AUTOSAR XML (schema 4-2-2)
package /ComponentTypes
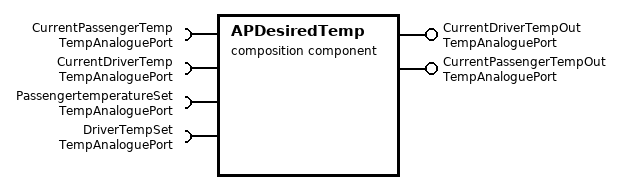
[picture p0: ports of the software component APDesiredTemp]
  composition sw component type APDesiredTemp
    require port CurrentPassengerTemp: required-interface=TempAnaloguePort
    require port CurrentDriverTemp: required-interface=TempAnaloguePort
    provide port CurrentDriverTempOut: provided-interface=TempAnaloguePort
    provide port CurrentPassengerTempOut: provided-interface=TempAnaloguePort
    require port PassengertemperatureSet: required-interface=TempAnaloguePort
    require port DriverTempSet: required-interface=TempAnaloguePort
    component Driver: type=CabinTempController
    component Passenger: type=CabinTempController
    delegate Driver.currentTemp <-> outer port CurrentDriverTemp
    delegate Passenger.currentTemp <-> outer port CurrentPassengerTemp
    delegate Passenger.tempOut <-> outer port CurrentPassengerTempOut
    delegate Driver.tempOut <-> outer port CurrentDriverTempOut
    delegate Driver.setTemp <-> outer port DriverTempSet
    delegate Passenger.setTemp <-> outer port PassengertemperatureSet
